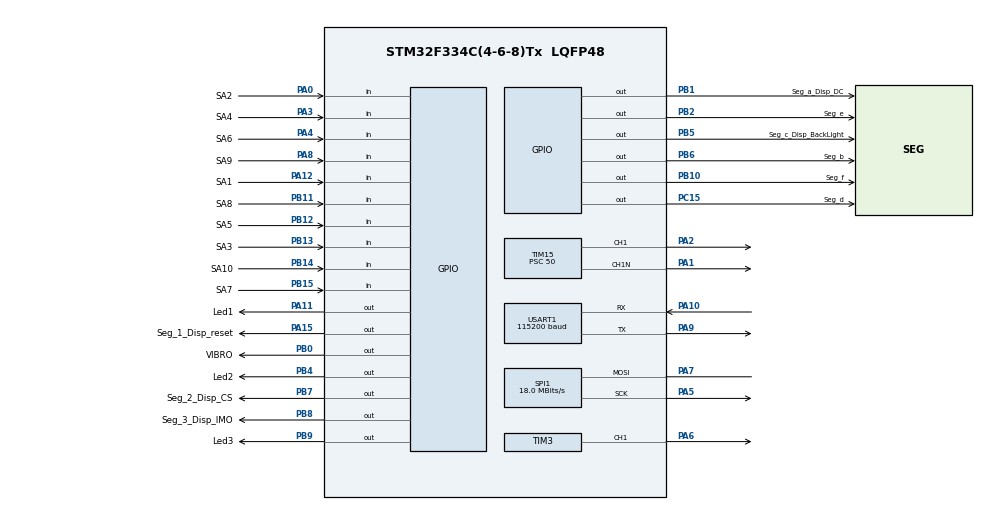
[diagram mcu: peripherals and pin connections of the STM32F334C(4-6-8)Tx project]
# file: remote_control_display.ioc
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CRC.InputDataInversionMode=CRC_INPUTDATA_INVERSION_NONE
CRC.OutputDataInversionMode=CRC_OUTPUTDATA_INVERSION_DISABLE
Dma.Request0=USART1_RX
Dma.Request1=USART1_TX
Dma.USART1_RX.0.Direction=DMA_PERIPH_TO_MEMORY
Dma.USART1_RX.0.Instance=DMA1_Channel5
Dma.USART1_RX.0.MemDataAlignment=DMA_MDATAALIGN_BYTE
Dma.USART1_RX.0.MemInc=DMA_MINC_ENABLE
Dma.USART1_RX.0.Mode=DMA_NORMAL
Dma.USART1_RX.0.PeriphDataAlignment=DMA_PDATAALIGN_BYTE
Dma.USART1_RX.0.PeriphInc=DMA_PINC_DISABLE
Dma.USART1_RX.0.Priority=DMA_PRIORITY_MEDIUM
Dma.USART1_TX.1.Direction=DMA_MEMORY_TO_PERIPH
Dma.USART1_TX.1.Instance=DMA1_Channel4
Dma.USART1_TX.1.MemDataAlignment=DMA_MDATAALIGN_BYTE
Dma.USART1_TX.1.MemInc=DMA_MINC_ENABLE
Dma.USART1_TX.1.Mode=DMA_NORMAL
Dma.USART1_TX.1.PeriphDataAlignment=DMA_PDATAALIGN_BYTE
Dma.USART1_TX.1.PeriphInc=DMA_PINC_DISABLE
Dma.USART1_TX.1.Priority=DMA_PRIORITY_MEDIUM
IWDG.Prescaler=IWDG_PRESCALER_128
IWDG.Reload=289
IWDG.Window=289
Mcu.Family=STM32F3
Mcu.Name=STM32F334C(4-6-8)Tx
Mcu.Package=LQFP48
Mcu.UserConstants=FREQUENCY_STEP,71
NVIC.DMA1_Channel4_IRQn=true\:0\:0\:false\:false\:true\:false\:true
NVIC.DMA1_Channel5_IRQn=true\:0\:0\:false\:false\:true\:false\:true
NVIC.PVD_IRQn=true\:1\:0\:true\:false\:true\:true\:true
NVIC.PriorityGroup=NVIC_PRIORITYGROUP_4
NVIC.RCC_IRQn=true\:1\:0\:true\:false\:true\:true\:false
NVIC.TIM1_BRK_TIM15_IRQn=true\:0\:0\:false\:false\:true\:true\:true
NVIC.TIM2_IRQn=true\:1\:0\:true\:false\:true\:true\:true
NVIC.TIM3_IRQn=true\:1\:0\:true\:false\:true\:true\:true
PA0.GPIO_Label=SA2
PA0.Signal=GPIO_Input
PA1.Mode=PWM Generation1 CH1 CH1N
PA1.Signal=TIM15_CH1N
PA10.GPIO_Speed=GPIO_SPEED_FREQ_LOW
PA10.Mode=Asynchronous
PA10.Signal=USART1_RX
PA11.GPIO_Label=Led1
PA11.GPIO_ModeDefaultOutputPP=GPIO_MODE_OUTPUT_OD
PA11.GPIO_PuPd=GPIO_PULLUP
PA11.Signal=GPIO_Output
PA12.GPIO_Label=SA1
PA12.Signal=GPIO_Input
PA13.Mode=Serial_Wire
PA13.Signal=SYS_JTMS-SWDIO
PA14.Mode=Serial_Wire
PA14.Signal=SYS_JTCK-SWCLK
PA15.GPIO_Label=Seg_1_Disp_reset
PA15.Signal=GPIO_Output
PA2.Signal=S_TIM15_CH1
PA3.GPIO_Label=SA4
PA3.Signal=GPIO_Input
PA4.GPIO_Label=SA6
PA4.Signal=GPIO_Input
PA5.GPIO_Speed=GPIO_SPEED_FREQ_LOW
PA5.Mode=Simplex_Bidirectional_Master
PA5.Signal=SPI1_SCK
PA6.Signal=S_TIM3_CH1
PA7.GPIO_Speed=GPIO_SPEED_FREQ_LOW
PA7.Mode=Simplex_Bidirectional_Master
PA7.Signal=SPI1_MOSI
PA8.GPIO_Label=SA9
PA8.Signal=GPIO_Input
PA9.GPIO_Speed=GPIO_SPEED_FREQ_LOW
PA9.Mode=Asynchronous
PA9.Signal=USART1_TX
PB0.GPIO_Label=VIBRO
PB0.Signal=GPIO_Output
PB1.GPIO_Label=Seg_a_Disp_DC
PB1.Signal=GPIO_Output
PB10.GPIO_Label=Seg_f
PB10.Signal=GPIO_Output
PB11.GPIO_Label=SA8
PB11.Signal=GPIO_Input
PB12.GPIO_Label=SA5
PB12.Signal=GPIO_Input
PB13.GPIO_Label=SA3
PB13.Signal=GPIO_Input
PB14.GPIO_Label=SA10
PB14.Signal=GPIO_Input
PB15.GPIO_Label=SA7
PB15.Signal=GPIO_Input
PB2.GPIO_Label=Seg_e
PB2.Signal=GPIO_Output
PB4.GPIO_Label=Led2
PB4.GPIO_ModeDefaultOutputPP=GPIO_MODE_OUTPUT_OD
PB4.GPIO_PuPd=GPIO_PULLUP
PB4.Signal=GPIO_Output
PB5.GPIO_Label=Seg_c_Disp_BackLight
PB5.Signal=GPIO_Output
PB6.GPIO_Label=Seg_b
PB6.Signal=GPIO_Output
PB7.GPIO_Label=Seg_2_Disp_CS
PB7.Signal=GPIO_Output
PB8.GPIO_Label=Seg_3_Disp_IMO
PB8.Signal=GPIO_Output
PB9.GPIO_Label=Led3
PB9.GPIO_ModeDefaultOutputPP=GPIO_MODE_OUTPUT_OD
PB9.GPIO_PuPd=GPIO_PULLUP
PB9.Signal=GPIO_Output
PC13.Mode=SYS_WakeUp1
PC13.Signal=SYS_WKUP2
PC15\ /\ OSC32_OUT.GPIO_Label=Seg_d
PC15\ /\ OSC32_OUT.Signal=GPIO_Output
PF0\ /\ OSC_IN.Mode=HSE-External-Oscillator
PF0\ /\ OSC_IN.Signal=RCC_OSC_IN
PF1\ /\ OSC_OUT.Mode=HSE-External-Oscillator
PF1\ /\ OSC_OUT.Signal=RCC_OSC_OUT
ProjectManager.HeapSize=0x200
ProjectManager.StackSize=0x400
ProjectManager.TargetToolchain=MDK-ARM V5.27
RCC.AHBFreq_Value=72000000
RCC.APB1CLKDivider=RCC_HCLK_DIV2
RCC.APB1Freq_Value=36000000
RCC.APB1TimFreq_Value=72000000
RCC.APB2Freq_Value=72000000
RCC.APB2TimFreq_Value=72000000
RCC.CortexFreq_Value=72000000
RCC.HCLKFreq_Value=72000000
RCC.HSE_VALUE=8000000
RCC.HSI_VALUE=8000000
RCC.LSE_VALUE=32768
RCC.PLLMUL=RCC_PLL_MUL9
RCC.PLLSourceVirtual=RCC_PLLSOURCE_HSE
RCC.SYSCLKFreq_VALUE=72000000
RCC.SYSCLKSourceVirtual=RCC_SYSCLKSOURCE_PLLCLK
SH.S_TIM15_CH1.0=TIM15_CH1,PWM Generation1 CH1 CH1N
SH.S_TIM3_CH1.0=TIM3_CH1,PWM Generation1 CH1
SPI1.BaudRatePrescaler=SPI_BAUDRATEPRESCALER_4
SPI1.CalculateBaudRate=18.0 MBits/s
SPI1.DataSize=SPI_DATASIZE_9BIT
SPI1.Direction=SPI_DIRECTION_1LINE
SPI1.Mode=SPI_MODE_MASTER
SPI1.NSSPMode=SPI_NSS_PULSE_DISABLE
SPI1.VirtualType=VM_MASTER
TIM15.Channel-PWM\ Generation1\ CH1\ CH1N=TIM_CHANNEL_1
TIM15.Period=30
TIM15.Prescaler=50
TIM2.AutoReloadPreload=TIM_AUTORELOAD_PRELOAD_ENABLE
TIM2.Period=2000
TIM2.Prescaler=719
TIM2.TIM_MasterOutputTrigger=TIM_TRGO_UPDATE
TIM2.TIM_MasterSlaveMode=TIM_MASTERSLAVEMODE_ENABLE
TIM3.AutoReloadPreload=TIM_AUTORELOAD_PRELOAD_ENABLE
TIM3.Channel-PWM\ Generation1\ CH1=TIM_CHANNEL_1
TIM3.CounterMode=TIM_COUNTERMODE_UP
TIM3.Period=2
TIM3.Prescaler=359
USART1.BaudRate=115200
USART1.VirtualMode-Asynchronous=VM_ASYNC
VP_CRC_VS_CRC.Mode=CRC_Activate
VP_IWDG_VS_IWDG.Mode=IWDG_Activate
VP_TIM15_VS_ClockSourceITR.Mode=TriggerSource_ITR0
VP_TIM15_VS_ControllerModeClock.Mode=Clock Mode
VP_TIM2_VS_ClockSourceINT.Mode=Internal
VP_TIM3_VS_ClockSourceINT.Mode=Internal
board=custom

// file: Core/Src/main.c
/* USER CODE BEGIN Header */
/**
  ******************************************************************************
  * @file           : main.c
  * @brief          : Main program body
  ******************************************************************************
  * @attention
  *
  * <h2><center>&copy; Copyright (c) 2021 STMicroelectronics.
  * All rights reserved.</center></h2>
  *
  * This software component is licensed by ST under BSD 3-Clause license,
  * the "License"; You may not use this file except in compliance with the
  * License. You may obtain a copy of the License at:
  *                        opensource.org/licenses/BSD-3-Clause
  *
  ******************************************************************************
  */
/* USER CODE END Header */
#include "main.h"
#include "crc.h"
#include "dma.h"
#include "iwdg.h"
#include "spi.h"
#include "tim.h"
#include "usart.h"
#include "gpio.h"

/* USER CODE BEGIN Includes */
#pragma import(__use_no_heap_region) //Запрет на использование кучи
/* USER CODE END Includes */

/* USER CODE BEGIN PV */
//volatile extern uint8_t timerOff;

/* USER CODE END PV */

void SystemClock_Config(void);

int main(void)
{

  /* MCU Configuration--------------------------------------------------------*/

  /* Reset of all peripherals, Initializes the Flash interface and the Systick. */

  LL_APB2_GRP1_EnableClock(LL_APB2_GRP1_PERIPH_SYSCFG);
  LL_APB1_GRP1_EnableClock(LL_APB1_GRP1_PERIPH_PWR);

  NVIC_SetPriorityGrouping(NVIC_PRIORITYGROUP_4);

  /* System interrupt init*/
  /* MemoryManagement_IRQn interrupt configuration */
  NVIC_SetPriority(MemoryManagement_IRQn, NVIC_EncodePriority(NVIC_GetPriorityGrouping(),1, 0));
  /* BusFault_IRQn interrupt configuration */
  NVIC_SetPriority(BusFault_IRQn, NVIC_EncodePriority(NVIC_GetPriorityGrouping(),1, 0));
  /* UsageFault_IRQn interrupt configuration */
  NVIC_SetPriority(UsageFault_IRQn, NVIC_EncodePriority(NVIC_GetPriorityGrouping(),1, 0));
  /* SVCall_IRQn interrupt configuration */
  NVIC_SetPriority(SVCall_IRQn, NVIC_EncodePriority(NVIC_GetPriorityGrouping(),1, 0));
  /* DebugMonitor_IRQn interrupt configuration */
  NVIC_SetPriority(DebugMonitor_IRQn, NVIC_EncodePriority(NVIC_GetPriorityGrouping(),1, 0));
  /* PendSV_IRQn interrupt configuration */
  NVIC_SetPriority(PendSV_IRQn, NVIC_EncodePriority(NVIC_GetPriorityGrouping(),1, 0));
  /* SysTick_IRQn interrupt configuration */
  NVIC_SetPriority(SysTick_IRQn, NVIC_EncodePriority(NVIC_GetPriorityGrouping(),1, 0));

  /* Peripheral interrupt init*/
  /* PVD_IRQn interrupt configuration */
  NVIC_SetPriority(PVD_IRQn, NVIC_EncodePriority(NVIC_GetPriorityGrouping(),1, 0));
  NVIC_EnableIRQ(PVD_IRQn);
  /* RCC_IRQn interrupt configuration */
  NVIC_SetPriority(RCC_IRQn, NVIC_EncodePriority(NVIC_GetPriorityGrouping(),1, 0));
  NVIC_EnableIRQ(RCC_IRQn);

  /* Configure the system clock */
  SystemClock_Config();

  /* Initialize all configured peripherals */
  MX_GPIO_Init();
  LL_GPIO_ResetOutputPin(Seg_c_Disp_BackLight_GPIO_Port, Seg_c_Disp_BackLight_Pin);
  LL_GPIO_SetOutputPin(Led1_GPIO_Port, Led1_Pin);
	LL_GPIO_SetOutputPin(Led2_GPIO_Port, Led2_Pin);
	LL_GPIO_SetOutputPin(Led3_GPIO_Port, Led3_Pin);
  LL_mDelay(100);
  //GLOBAL_FLAG_TX |= TEST_FLAG;
  if	((LL_GPIO_IsInputPinSet(SA6_GPIO_Port, SA6_Pin) == 1) &&
       (LL_GPIO_IsInputPinSet(SA7_GPIO_Port, SA7_Pin) == 1))
  {
    if (LL_GPIO_IsInputPinSet(SA1_GPIO_Port, SA1_Pin) == 1)
    { //Тестирование всех моторов по очереди
      LL_IWDG_ReloadCounter(IWDG);
      GLOBAL_TEST_FLAG |= TEST_ALLMOTORS_FLAG;
      GLOBAL_FLAG_TX |= TEST_FLAG;
    }
    else if (LL_GPIO_IsInputPinSet(SA2_GPIO_Port, SA2_Pin) == 1)
    { //Тестирование ДПТ вперед-назад
      LL_IWDG_ReloadCounter(IWDG);
      GLOBAL_TEST_FLAG |= TEST_BDC_FLAG;
      GLOBAL_FLAG_TX |= TEST_FLAG;
    }
    else if (LL_GPIO_IsInputPinSet(SA3_GPIO_Port, SA3_Pin) == 1)
    { //Тестирование BLDC вверх-вниз
      LL_IWDG_ReloadCounter(IWDG);
      GLOBAL_TEST_FLAG |= TEST_BLDC_FLAG;
      GLOBAL_FLAG_TX |= TEST_FLAG;
    }
    else if (LL_GPIO_IsInputPinSet(SA4_GPIO_Port, SA4_Pin) == 1)
    { //Тестирование ШД сильнее-слабее
      LL_IWDG_ReloadCounter(IWDG);
      GLOBAL_TEST_FLAG |= TEST_STEP_FLAG;
      GLOBAL_FLAG_TX |= TEST_FLAG;
    }
  }
  MX_SPI1_Init();
  MX_DMA_Init();
  MX_TIM2_Init();
  MX_TIM3_Init();
  MX_USART1_UART_Init();

  MX_CRC_Init();
  if (!(GLOBAL_FLAG_TX & TEST_FLAG) )
  {
    MX_IWDG_Init();
    MX_TIM15_Init();
    SleepAfterWatchDog();
  }
  else
  {
//    speed = 0;
    Sound_PWM(4000, 30);
//    LL_TIM_SetPrescaler(TIM_Sound, 2000);
//    Sound_Play(track_sw);
//    LL_TIM_SetPrescaler(TIM_Sound, 359);
  }

  /* USER CODE BEGIN 2 */

	StartUpConfig();
 // Sound_Play(track_sw);
 // LL_mDelay(500);
  /* USER CODE END 2 */

  /* Infinite loop */
  /* USER CODE BEGIN WHILE */
  while (1)
  {
    if (!(GLOBAL_FLAG_TX & TEST_FLAG) )
    {
      ScanButton();
      ResetTIM_Sleep();
      LL_IWDG_ReloadCounter(IWDG);
    }
    else
    {
      TestButtonPress();
    }
    DisplayOut(battery, speed, weight);
    Sound_Player((uint8_t *)Sound_track);
    /* USER CODE END WHILE */

  }
}

void SystemClock_Config(void)
{
  LL_FLASH_SetLatency(LL_FLASH_LATENCY_2);
  while(LL_FLASH_GetLatency()!= LL_FLASH_LATENCY_2)
  {
  }
  LL_RCC_HSE_Enable();

   /* Wait till HSE is ready */
  while(LL_RCC_HSE_IsReady() != 1)
  {

  }
  LL_RCC_LSI_Enable();

   /* Wait till LSI is ready */
  while(LL_RCC_LSI_IsReady() != 1)
  {

  }
  LL_RCC_PLL_ConfigDomain_SYS(LL_RCC_PLLSOURCE_HSE_DIV_1, LL_RCC_PLL_MUL_9);
  LL_RCC_PLL_Enable();

   /* Wait till PLL is ready */
  while(LL_RCC_PLL_IsReady() != 1)
  {

  }
  LL_RCC_SetAHBPrescaler(LL_RCC_SYSCLK_DIV_1);
  LL_RCC_SetAPB1Prescaler(LL_RCC_APB1_DIV_2);
  LL_RCC_SetAPB2Prescaler(LL_RCC_APB2_DIV_1);
  LL_RCC_SetSysClkSource(LL_RCC_SYS_CLKSOURCE_PLL);

   /* Wait till System clock is ready */
  while(LL_RCC_GetSysClkSource() != LL_RCC_SYS_CLKSOURCE_STATUS_PLL)
  {

  }
  LL_Init1msTick(72000000);
  LL_SetSystemCoreClock(72000000);
  LL_RCC_SetUSARTClockSource(LL_RCC_USART1_CLKSOURCE_PCLK1);
}

void Error_Handler(void)
{
}
